VERSION "DBC_LIGHTS_RELAIS_FRONT"

NS_ :

BS_:

BU_:

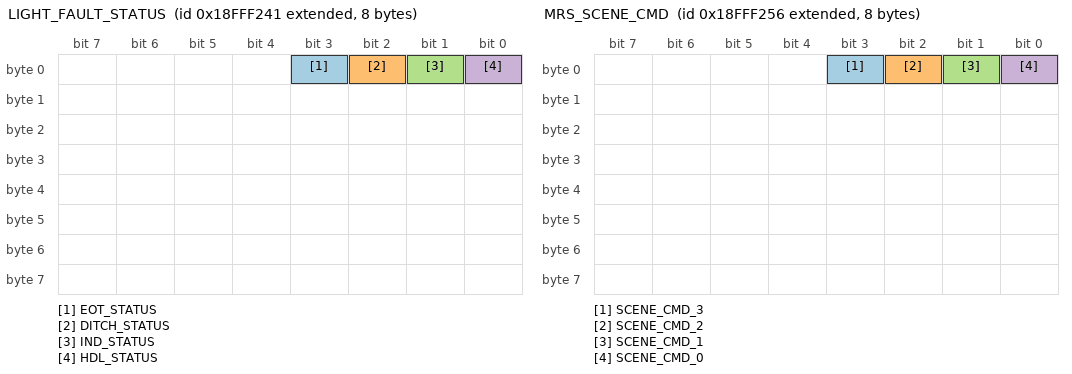
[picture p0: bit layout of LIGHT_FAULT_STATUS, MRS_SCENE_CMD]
BO_ 2566910529 LIGHT_FAULT_STATUS: 8 Vector__XXX
 SG_ EOT_STATUS : 3|1@1+ (1,0) [0|1] "Binary" Vector__XXX
 SG_ DITCH_STATUS : 2|1@1+ (1,0) [0|1] "Binary" Vector__XXX
 SG_ IND_STATUS : 1|1@1+ (1,0) [0|1] "Binary" Vector__XXX
 SG_ HDL_STATUS : 0|1@1+ (1,0) [0|1] "Binary" Vector__XXX

BO_ 2566910550 MRS_SCENE_CMD: 8 Vector__XXX
 SG_ SCENE_CMD_3 : 3|1@1+ (1,0) [0|1] "Binary" Vector__XXX
 SG_ SCENE_CMD_2 : 2|1@1+ (1,0) [0|1] "Binary" Vector__XXX
 SG_ SCENE_CMD_1 : 1|1@1+ (1,0) [0|1] "Binary" Vector__XXX
 SG_ SCENE_CMD_0 : 0|1@1+ (1,0) [0|1] "Binary" Vector__XXX

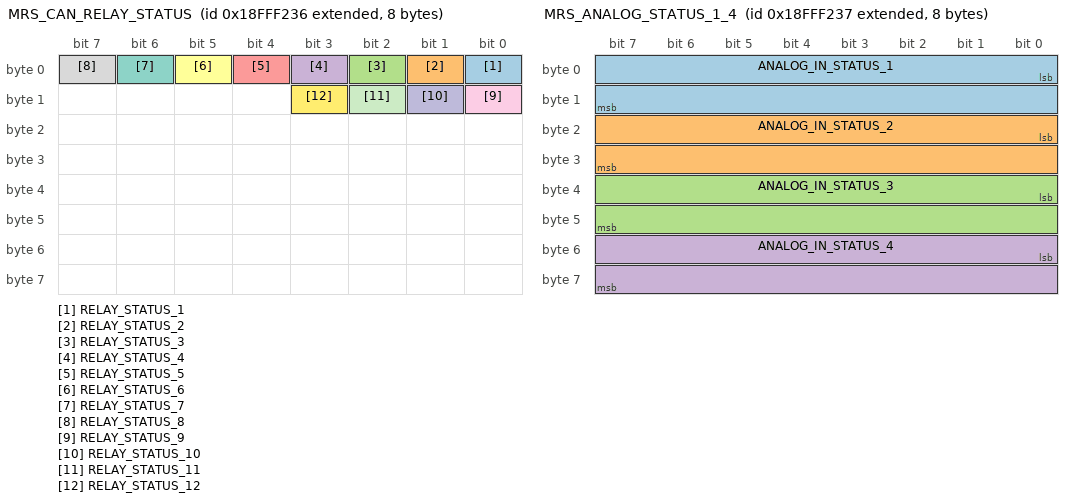
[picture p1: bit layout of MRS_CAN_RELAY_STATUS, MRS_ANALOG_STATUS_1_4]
BO_ 2566910518 MRS_CAN_RELAY_STATUS: 8 Vector__XXX
 SG_ RELAY_STATUS_1 : 0|1@1+ (1,0) [0|1] "Binary" Vector__XXX
 SG_ RELAY_STATUS_2 : 1|1@1+ (1,0) [0|1] "Binary" Vector__XXX
 SG_ RELAY_STATUS_3 : 2|1@1+ (1,0) [0|1] "Binary" Vector__XXX
 SG_ RELAY_STATUS_4 : 3|1@1+ (1,0) [0|1] "Binary" Vector__XXX
 SG_ RELAY_STATUS_5 : 4|1@1+ (1,0) [0|1] "Binary" Vector__XXX
 SG_ RELAY_STATUS_6 : 5|1@1+ (1,0) [0|1] "Binary" Vector__XXX
 SG_ RELAY_STATUS_7 : 6|1@1+ (1,0) [0|1] "Binary" Vector__XXX
 SG_ RELAY_STATUS_8 : 7|1@1+ (1,0) [0|1] "Binary" Vector__XXX
 SG_ RELAY_STATUS_9 : 8|1@1+ (1,0) [0|1] "Binary" Vector__XXX
 SG_ RELAY_STATUS_10 : 9|1@1+ (1,0) [0|1] "Binary" Vector__XXX
 SG_ RELAY_STATUS_11 : 10|1@1+ (1,0) [0|1] "Binary" Vector__XXX
 SG_ RELAY_STATUS_12 : 11|1@1+ (1,0) [0|1] "Binary" Vector__XXX

BO_ 2566910519 MRS_ANALOG_STATUS_1_4: 8 Vector__XXX
 SG_ ANALOG_IN_STATUS_1 : 0|16@1+ (0.0002,0) [0|11.34] "V" Vector__XXX
 SG_ ANALOG_IN_STATUS_2 : 16|16@1+ (0.0002,0) [0|11.34] "V" Vector__XXX
 SG_ ANALOG_IN_STATUS_3 : 32|16@1+ (0.0002,0) [0|11.34] "V" Vector__XXX
 SG_ ANALOG_IN_STATUS_4 : 48|16@1+ (0.0002,0) [0|11.34] "V" Vector__XXX

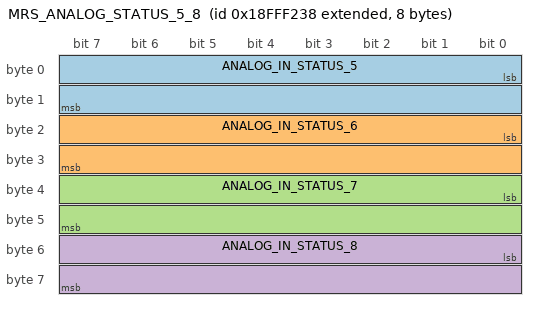
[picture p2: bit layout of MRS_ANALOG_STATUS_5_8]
BO_ 2566910520 MRS_ANALOG_STATUS_5_8: 8 Vector__XXX
 SG_ ANALOG_IN_STATUS_5 : 0|16@1+ (0.0002,0) [0|11.34] "V" Vector__XXX
 SG_ ANALOG_IN_STATUS_6 : 16|16@1+ (0.0002,0) [0|11.34] "V" Vector__XXX
 SG_ ANALOG_IN_STATUS_7 : 32|16@1+ (0.0002,0) [0|11.34] "V" Vector__XXX
 SG_ ANALOG_IN_STATUS_8 : 48|16@1+ (0.0002,0) [0|11.34] "V" Vector__XXX

BA_DEF_ BO_  "VFrameFormat" ENUM  "StandardCAN","ExtendedCAN","reserved","J1939PG";
BA_DEF_  "DatabaseVersion" STRING ;
BA_DEF_  "BusType" STRING ;
BA_DEF_  "ProtocolType" STRING ;
BA_DEF_  "DatabaseCompiler" STRING ;
BA_DEF_DEF_  "VFrameFormat" "J1939PG";
BA_DEF_DEF_  "DatabaseVersion" "DEMO PLUS";
BA_DEF_DEF_  "BusType" "";
BA_DEF_DEF_  "ProtocolType" "";
BA_DEF_DEF_  "DatabaseCompiler" "";
BA_ "ProtocolType" "J1939";
BA_ "BusType" "CAN";
BA_ "DatabaseCompiler" "CSS ELECTRONICS (WWW.CSSELECTRONICS.COM)";
BA_ "DatabaseVersion" "1.0.0";
BA_ "VFrameFormat" BO_ 2566910529 1;
BA_ "VFrameFormat" BO_ 2566910550 1;
BA_ "VFrameFormat" BO_ 2566910518 1;
BA_ "VFrameFormat" BO_ 2566910519 1;
BA_ "VFrameFormat" BO_ 2566910520 1;
